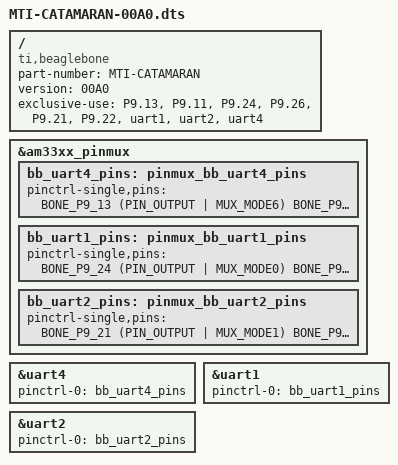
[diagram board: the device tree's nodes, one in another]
/*
 * Copyright (C) 2013 CircuitCo
 *
 * Virtual cape for UART4 on connector pins P9.13 P9.11
 *
 * This program is free software; you can redistribute it and/or modify
 * it under the terms of the GNU General Public License version 2 as
 * published by the Free Software Foundation.
 */
/dts-v1/;
/plugin/;

#include <dt-bindings/board/am335x-bbw-bbb-base.h>
#include <dt-bindings/pinctrl/am33xx.h>

/ {
	compatible = "ti,beaglebone", "ti,beaglebone-black", "ti,beaglebone-green";

	// identification
	part-number = "MTI-CATAMARAN";
	version = "00A0";

	// resources this cape uses
	exclusive-use =
		"P9.13",		// uart4_txd
		"P9.11",		// uart4_rxd
    "P9.24",		// uart1_txd
		"P9.26",		// uart1_rxd
    "P9.21",		// uart2_txd
		"P9.22",		// uart2_rxd

    "uart1",
    "uart2",
		"uart4";		// hardware ip used

	fragment@0 {
		target = <&am33xx_pinmux>;
		__overlay__ {
			bb_uart4_pins: pinmux_bb_uart4_pins {
				pinctrl-single,pins = <
					BONE_P9_13 (PIN_OUTPUT | MUX_MODE6)	// gpmc_wpn.uart4_txd_mux2
					BONE_P9_11 (PIN_INPUT  | MUX_MODE6)	// gpmc_wait0.uart4_rxd_mux2
				>;
			};
		};
	};

	fragment@1 {
		target = <&uart4>;
		__overlay__ {
			status = "okay";
			pinctrl-names = "default";
			pinctrl-0 = <&bb_uart4_pins>;
		};
	};

  fragment@2 {
    target = <&am33xx_pinmux>;
    __overlay__ {
      bb_uart1_pins: pinmux_bb_uart1_pins {
        pinctrl-single,pins = <
          BONE_P9_24 (PIN_OUTPUT | MUX_MODE0)	// uart1_txd.uart1_txd
          BONE_P9_26 (PIN_INPUT | MUX_MODE0)	// uart1_rxd.uart1_rxd
        >;
      };
    };
  };

  fragment@3 {
    target = <&uart1>;
    __overlay__ {
      status = "okay";
      pinctrl-names = "default";
      pinctrl-0 = <&bb_uart1_pins>;
    };
  };

  fragment@4 {
    target = <&am33xx_pinmux>;
    __overlay__ {
      bb_uart2_pins: pinmux_bb_uart2_pins {
        pinctrl-single,pins = <
          BONE_P9_21 (PIN_OUTPUT | MUX_MODE1)	// spi0_d0.uart2_txd
          BONE_P9_22 (PIN_INPUT  | MUX_MODE1)	// spi0_sclk.uart2_rxd
        >;
      };
    };
  };

  fragment@5 {
    target = <&uart2>;
    __overlay__ {
      status = "okay";
      pinctrl-names = "default";
      pinctrl-0 = <&bb_uart2_pins>;
    };
  };
};
